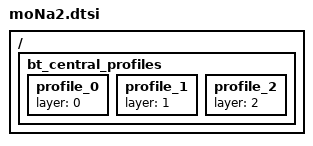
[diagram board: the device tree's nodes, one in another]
/ {
    bt_central_profiles {
        profile_0 {
            layer = 0; // Windows
        };
        profile_1 {
            layer = 1; // macOS
        };
        profile_2 {
            layer = 2; // iPad
        };
    };
};
